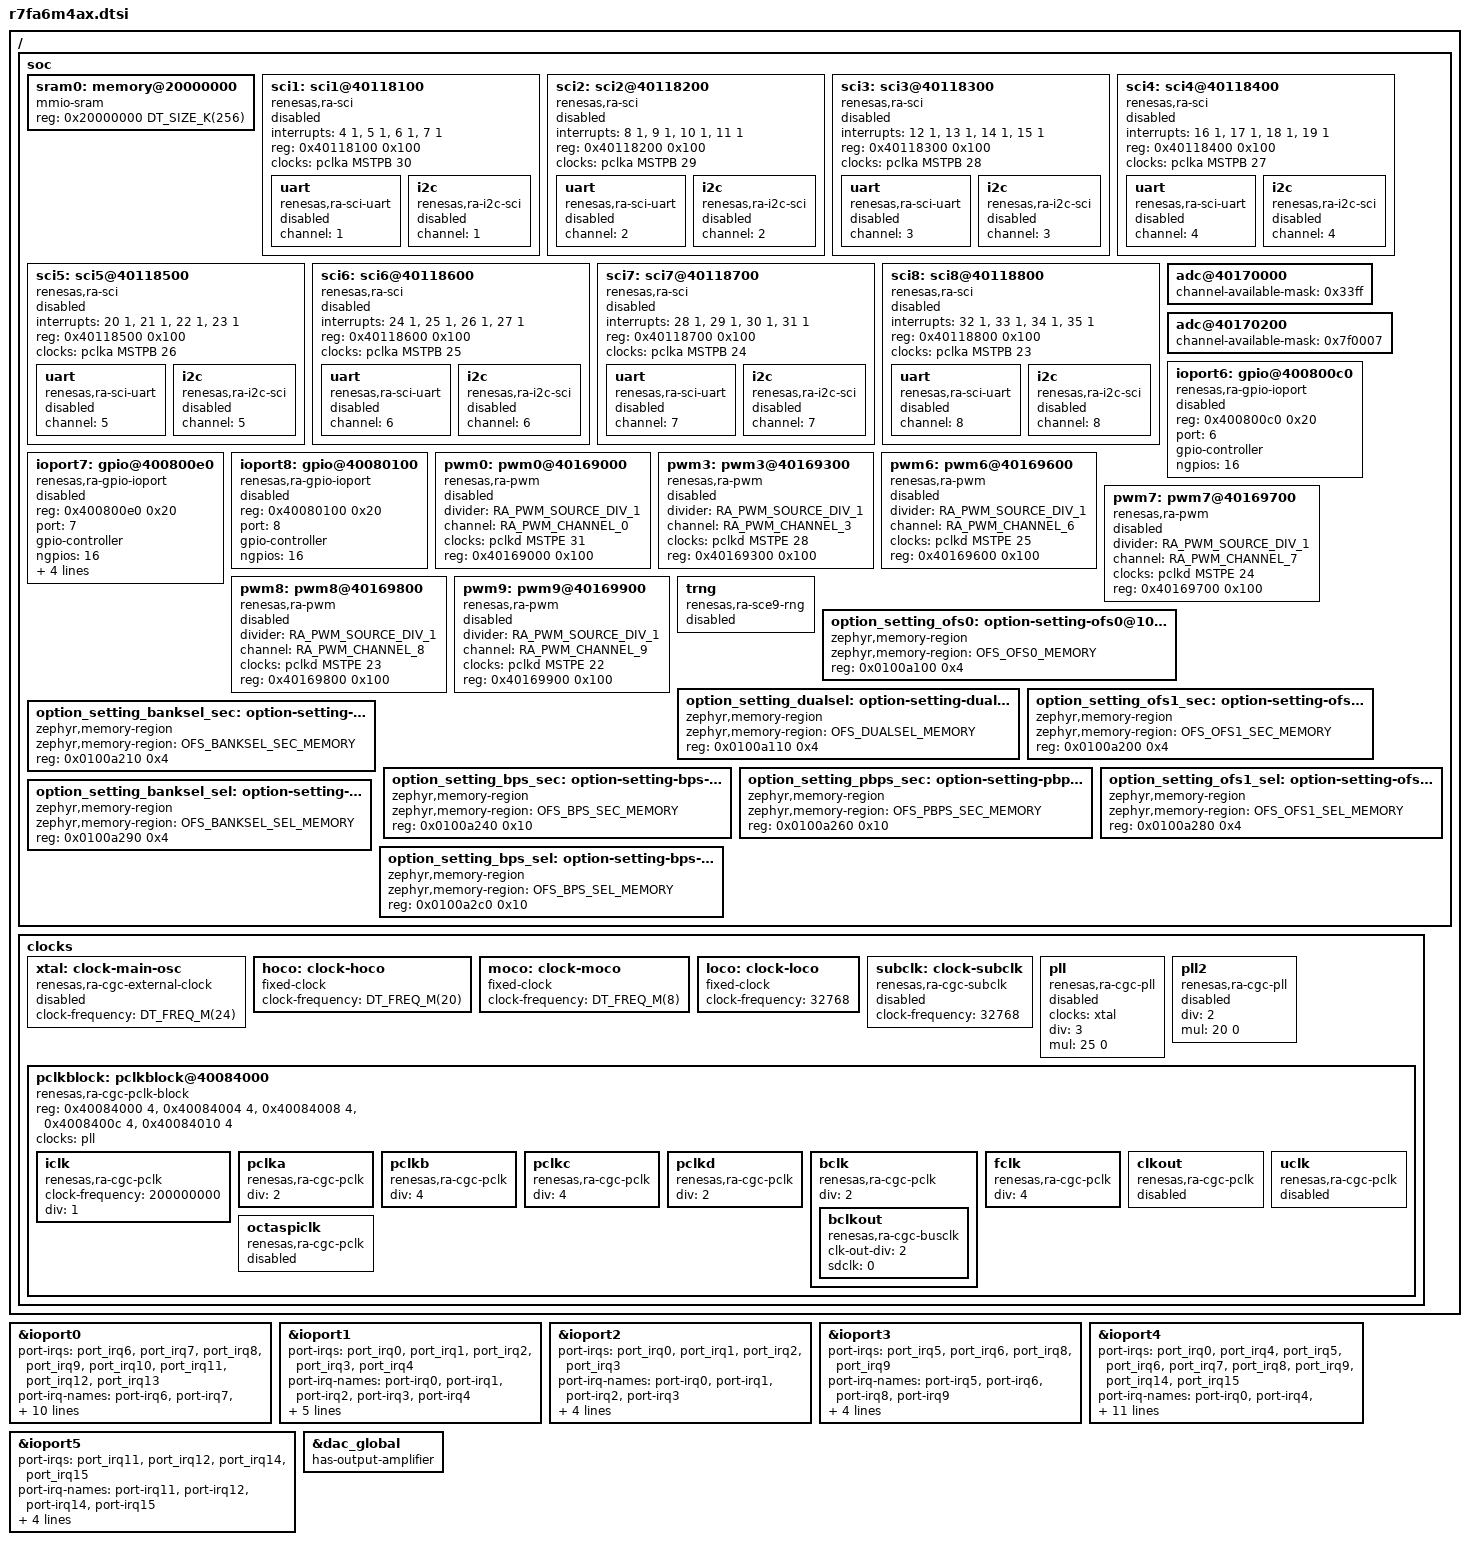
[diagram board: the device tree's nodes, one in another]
/*
 * Copyright (c) 2024-2025 Renesas Electronics Corporation
 *
 * SPDX-License-Identifier: Apache-2.0
 */

#include <arm/renesas/ra/ra6/ra6-cm33-common.dtsi>
#include <zephyr/dt-bindings/clock/ra_clock.h>
#include <zephyr/dt-bindings/pwm/ra_pwm.h>
#include <zephyr/dt-bindings/misc/renesas/ra-elc/ra6m4-elc.h>

/ {
	soc {
		sram0: memory@20000000 {
			compatible = "mmio-sram";
			reg = <0x20000000 DT_SIZE_K(256)>;
		};

		sci1: sci1@40118100 {
			compatible = "renesas,ra-sci";
			interrupts = <4 1>, <5 1>, <6 1>, <7 1>;
			interrupt-names = "rxi", "txi", "tei", "eri";
			reg = <0x40118100 0x100>;
			clocks = <&pclka MSTPB 30>;
			status = "disabled";

			uart {
				compatible = "renesas,ra-sci-uart";
				channel = <1>;
				status = "disabled";
			};

			i2c {
				compatible = "renesas,ra-i2c-sci";
				#address-cells = <1>;
				#size-cells = <0>;
				channel = <1>;
				status = "disabled";
			};
		};

		sci2: sci2@40118200 {
			compatible = "renesas,ra-sci";
			interrupts = <8 1>, <9 1>, <10 1>, <11 1>;
			interrupt-names = "rxi", "txi", "tei", "eri";
			reg = <0x40118200 0x100>;
			clocks = <&pclka MSTPB 29>;
			status = "disabled";

			uart {
				compatible = "renesas,ra-sci-uart";
				channel = <2>;
				status = "disabled";
			};

			i2c {
				compatible = "renesas,ra-i2c-sci";
				#address-cells = <1>;
				#size-cells = <0>;
				channel = <2>;
				status = "disabled";
			};
		};

		sci3: sci3@40118300 {
			compatible = "renesas,ra-sci";
			interrupts = <12 1>, <13 1>, <14 1>, <15 1>;
			interrupt-names = "rxi", "txi", "tei", "eri";
			reg = <0x40118300 0x100>;
			clocks = <&pclka MSTPB 28>;
			status = "disabled";

			uart {
				compatible = "renesas,ra-sci-uart";
				channel = <3>;
				status = "disabled";
			};

			i2c {
				compatible = "renesas,ra-i2c-sci";
				#address-cells = <1>;
				#size-cells = <0>;
				channel = <3>;
				status = "disabled";
			};
		};

		sci4: sci4@40118400 {
			compatible = "renesas,ra-sci";
			interrupts = <16 1>, <17 1>, <18 1>, <19 1>;
			interrupt-names = "rxi", "txi", "tei", "eri";
			reg = <0x40118400 0x100>;
			clocks = <&pclka MSTPB 27>;
			status = "disabled";

			uart {
				compatible = "renesas,ra-sci-uart";
				channel = <4>;
				status = "disabled";
			};

			i2c {
				compatible = "renesas,ra-i2c-sci";
				#address-cells = <1>;
				#size-cells = <0>;
				channel = <4>;
				status = "disabled";
			};
		};

		sci5: sci5@40118500 {
			compatible = "renesas,ra-sci";
			interrupts = <20 1>, <21 1>, <22 1>, <23 1>;
			interrupt-names = "rxi", "txi", "tei", "eri";
			reg = <0x40118500 0x100>;
			clocks = <&pclka MSTPB 26>;
			status = "disabled";

			uart {
				compatible = "renesas,ra-sci-uart";
				channel = <5>;
				status = "disabled";
			};

			i2c {
				compatible = "renesas,ra-i2c-sci";
				#address-cells = <1>;
				#size-cells = <0>;
				channel = <5>;
				status = "disabled";
			};
		};

		sci6: sci6@40118600 {
			compatible = "renesas,ra-sci";
			interrupts = <24 1>, <25 1>, <26 1>, <27 1>;
			interrupt-names = "rxi", "txi", "tei", "eri";
			reg = <0x40118600 0x100>;
			clocks = <&pclka MSTPB 25>;
			status = "disabled";

			uart {
				compatible = "renesas,ra-sci-uart";
				channel = <6>;
				status = "disabled";
			};

			i2c {
				compatible = "renesas,ra-i2c-sci";
				#address-cells = <1>;
				#size-cells = <0>;
				channel = <6>;
				status = "disabled";
			};
		};

		sci7: sci7@40118700 {
			compatible = "renesas,ra-sci";
			interrupts = <28 1>, <29 1>, <30 1>, <31 1>;
			interrupt-names = "rxi", "txi", "tei", "eri";
			reg = <0x40118700 0x100>;
			clocks = <&pclka MSTPB 24>;
			status = "disabled";

			uart {
				compatible = "renesas,ra-sci-uart";
				channel = <7>;
				status = "disabled";
			};

			i2c {
				compatible = "renesas,ra-i2c-sci";
				#address-cells = <1>;
				#size-cells = <0>;
				channel = <7>;
				status = "disabled";
			};
		};

		sci8: sci8@40118800 {
			compatible = "renesas,ra-sci";
			interrupts = <32 1>, <33 1>, <34 1>, <35 1>;
			interrupt-names = "rxi", "txi", "tei", "eri";
			reg = <0x40118800 0x100>;
			clocks = <&pclka MSTPB 23>;
			status = "disabled";

			uart {
				compatible = "renesas,ra-sci-uart";
				channel = <8>;
				status = "disabled";
			};

			i2c {
				compatible = "renesas,ra-i2c-sci";
				#address-cells = <1>;
				#size-cells = <0>;
				channel = <8>;
				status = "disabled";
			};
		};

		adc@40170000 {
			channel-available-mask = <0x33ff>;
		};

		adc@40170200 {
			channel-available-mask = <0x7f0007>;
		};

		ioport6: gpio@400800c0 {
			compatible = "renesas,ra-gpio-ioport";
			reg = <0x400800c0 0x20>;
			port = <6>;
			gpio-controller;
			#gpio-cells = <2>;
			ngpios = <16>;
			status = "disabled";
		};

		ioport7: gpio@400800e0 {
			compatible = "renesas,ra-gpio-ioport";
			reg = <0x400800e0 0x20>;
			port = <7>;
			gpio-controller;
			#gpio-cells = <2>;
			ngpios = <16>;
			status = "disabled";
		};

		ioport8: gpio@40080100 {
			compatible = "renesas,ra-gpio-ioport";
			reg = <0x40080100 0x20>;
			port = <8>;
			gpio-controller;
			#gpio-cells = <2>;
			ngpios = <16>;
			status = "disabled";
		};

		pwm0: pwm0@40169000 {
			compatible = "renesas,ra-pwm";
			divider = <RA_PWM_SOURCE_DIV_1>;
			channel = <RA_PWM_CHANNEL_0>;
			clocks = <&pclkd MSTPE 31>;
			reg = <0x40169000 0x100>;
			#pwm-cells = <3>;
			status = "disabled";
		};

		pwm3: pwm3@40169300 {
			compatible = "renesas,ra-pwm";
			divider = <RA_PWM_SOURCE_DIV_1>;
			channel = <RA_PWM_CHANNEL_3>;
			clocks = <&pclkd MSTPE 28>;
			reg = <0x40169300 0x100>;
			#pwm-cells = <3>;
			status = "disabled";
		};

		pwm6: pwm6@40169600 {
			compatible = "renesas,ra-pwm";
			divider = <RA_PWM_SOURCE_DIV_1>;
			channel = <RA_PWM_CHANNEL_6>;
			clocks = <&pclkd MSTPE 25>;
			reg = <0x40169600 0x100>;
			#pwm-cells = <3>;
			status = "disabled";
		};

		pwm7: pwm7@40169700 {
			compatible = "renesas,ra-pwm";
			divider = <RA_PWM_SOURCE_DIV_1>;
			channel = <RA_PWM_CHANNEL_7>;
			clocks = <&pclkd MSTPE 24>;
			reg = <0x40169700 0x100>;
			#pwm-cells = <3>;
			status = "disabled";
		};

		pwm8: pwm8@40169800 {
			compatible = "renesas,ra-pwm";
			divider = <RA_PWM_SOURCE_DIV_1>;
			channel = <RA_PWM_CHANNEL_8>;
			clocks = <&pclkd MSTPE 23>;
			reg = <0x40169800 0x100>;
			#pwm-cells = <3>;
			status = "disabled";
		};

		pwm9: pwm9@40169900 {
			compatible = "renesas,ra-pwm";
			divider = <RA_PWM_SOURCE_DIV_1>;
			channel = <RA_PWM_CHANNEL_9>;
			clocks = <&pclkd MSTPE 22>;
			reg = <0x40169900 0x100>;
			#pwm-cells = <3>;
			status = "disabled";
		};

		trng: trng {
			compatible = "renesas,ra-sce9-rng";
			status = "disabled";
		};

		option_setting_ofs0: option-setting-ofs0@100a100 {
			compatible = "zephyr,memory-region";
			zephyr,memory-region = "OFS_OFS0_MEMORY";
			reg = <0x0100a100 0x4>;
			status = "okay";
		};

		option_setting_dualsel: option-setting-dualsel@100a110 {
			compatible = "zephyr,memory-region";
			zephyr,memory-region = "OFS_DUALSEL_MEMORY";
			reg = <0x0100a110 0x4>;
			status = "okay";
		};

		option_setting_ofs1_sec: option-setting-ofs1-sec@100a200 {
			compatible = "zephyr,memory-region";
			zephyr,memory-region = "OFS_OFS1_SEC_MEMORY";
			reg = <0x0100a200 0x4>;
			status = "okay";
		};

		option_setting_banksel_sec: option-setting-banksel-sec@100a210 {
			compatible = "zephyr,memory-region";
			zephyr,memory-region = "OFS_BANKSEL_SEC_MEMORY";
			reg = <0x0100a210 0x4>;
			status = "okay";
		};

		option_setting_bps_sec: option-setting-bps-sec@100a240 {
			compatible = "zephyr,memory-region";
			zephyr,memory-region = "OFS_BPS_SEC_MEMORY";
			reg = <0x0100a240 0x10>;
			status = "okay";
		};

		option_setting_pbps_sec: option-setting-pbps-sec@100a260 {
			compatible = "zephyr,memory-region";
			zephyr,memory-region = "OFS_PBPS_SEC_MEMORY";
			reg = <0x0100a260 0x10>;
			status = "okay";
		};

		option_setting_ofs1_sel: option-setting-ofs1-sel@100a280 {
			compatible = "zephyr,memory-region";
			zephyr,memory-region = "OFS_OFS1_SEL_MEMORY";
			reg = <0x0100a280 0x4>;
			status = "okay";
		};

		option_setting_banksel_sel: option-setting-banksel-sel@100a290 {
			compatible = "zephyr,memory-region";
			zephyr,memory-region = "OFS_BANKSEL_SEL_MEMORY";
			reg = <0x0100a290 0x4>;
			status = "okay";
		};

		option_setting_bps_sel: option-setting-bps-sel@100a2c0 {
			compatible = "zephyr,memory-region";
			zephyr,memory-region = "OFS_BPS_SEL_MEMORY";
			reg = <0x0100a2c0 0x10>;
			status = "okay";
		};
	};

	clocks: clocks {
		#address-cells = <1>;
		#size-cells = <1>;

		xtal: clock-main-osc {
			compatible = "renesas,ra-cgc-external-clock";
			clock-frequency = <DT_FREQ_M(24)>;
			#clock-cells = <0>;
			status = "disabled";
		};

		hoco: clock-hoco {
			compatible = "fixed-clock";
			clock-frequency = <DT_FREQ_M(20)>;
			#clock-cells = <0>;
		};

		moco: clock-moco {
			compatible = "fixed-clock";
			clock-frequency = <DT_FREQ_M(8)>;
			#clock-cells = <0>;
		};

		loco: clock-loco {
			compatible = "fixed-clock";
			clock-frequency = <32768>;
			#clock-cells = <0>;
		};

		subclk: clock-subclk {
			compatible = "renesas,ra-cgc-subclk";
			clock-frequency = <32768>;
			#clock-cells = <0>;
			status = "disabled";
		};

		pll: pll {
			compatible = "renesas,ra-cgc-pll";
			#clock-cells = <0>;

			/* PLL */
			clocks = <&xtal>;
			div = <3>;
			mul = <25 0>;
			status = "disabled";
		};

		pll2: pll2 {
			compatible = "renesas,ra-cgc-pll";
			#clock-cells = <0>;

			/* PLL2 */
			div = <2>;
			mul = <20 0>;
			status = "disabled";
		};

		pclkblock: pclkblock@40084000 {
			compatible = "renesas,ra-cgc-pclk-block";
			reg = <0x40084000 4>, <0x40084004 4>, <0x40084008 4>,
			      <0x4008400c 4>, <0x40084010 4>;
			reg-names = "MSTPA", "MSTPB", "MSTPC",
				    "MSTPD", "MSTPE";
			#clock-cells = <0>;
			clocks = <&pll>;
			status = "okay";

			iclk: iclk {
				compatible = "renesas,ra-cgc-pclk";
				clock-frequency = <200000000>;
				div = <1>;
				#clock-cells = <2>;
				status = "okay";
			};

			pclka: pclka {
				compatible = "renesas,ra-cgc-pclk";
				div = <2>;
				#clock-cells = <2>;
				status = "okay";
			};

			pclkb: pclkb {
				compatible = "renesas,ra-cgc-pclk";
				div = <4>;
				#clock-cells = <2>;
				status = "okay";
			};

			pclkc: pclkc {
				compatible = "renesas,ra-cgc-pclk";
				div = <4>;
				#clock-cells = <2>;
				status = "okay";
			};

			pclkd: pclkd {
				compatible = "renesas,ra-cgc-pclk";
				div = <2>;
				#clock-cells = <2>;
				status = "okay";
			};

			bclk: bclk {
				compatible = "renesas,ra-cgc-pclk";
				div = <2>;
				#clock-cells = <2>;
				status = "okay";

				bclkout: bclkout {
					compatible = "renesas,ra-cgc-busclk";
					clk-out-div = <2>;
					sdclk = <0>;
					#clock-cells = <0>;
				};
			};

			fclk: fclk {
				compatible = "renesas,ra-cgc-pclk";
				div = <4>;
				#clock-cells = <2>;
				status = "okay";
			};

			clkout: clkout {
				compatible = "renesas,ra-cgc-pclk";
				#clock-cells = <2>;
				status = "disabled";
			};

			uclk: uclk {
				compatible = "renesas,ra-cgc-pclk";
				#clock-cells = <2>;
				status = "disabled";
			};

			octaspiclk: octaspiclk {
				compatible = "renesas,ra-cgc-pclk";
				#clock-cells = <2>;
				status = "disabled";
			};
		};
	};
};

&ioport0 {
	port-irqs = <&port_irq6 &port_irq7 &port_irq8
		     &port_irq9 &port_irq10 &port_irq11
		     &port_irq12 &port_irq13>;
	port-irq-names = "port-irq6",
			 "port-irq7",
			 "port-irq8",
			 "port-irq9",
			 "port-irq10",
			 "port-irq11",
			 "port-irq12",
			 "port-irq13";
	port-irq6-pins = <0>;
	port-irq7-pins = <1>;
	port-irq8-pins = <2>;
	port-irq9-pins = <4>;
	port-irq10-pins = <5>;
	port-irq11-pins = <6>;
	port-irq12-pins = <8>;
	port-irq13-pins = <9 15>;
};

&ioport1 {
	port-irqs = <&port_irq0 &port_irq1 &port_irq2
		     &port_irq3 &port_irq4>;
	port-irq-names = "port-irq0",
			 "port-irq1",
			 "port-irq2",
			 "port-irq3",
			 "port-irq4";
	port-irq0-pins = <5>;
	port-irq1-pins = <1 4>;
	port-irq2-pins = <0>;
	port-irq3-pins = <10>;
	port-irq4-pins = <11>;
};

&ioport2 {
	port-irqs = <&port_irq0 &port_irq1 &port_irq2
		     &port_irq3>;
	port-irq-names = "port-irq0",
			 "port-irq1",
			 "port-irq2",
			 "port-irq3";
	port-irq0-pins = <6>;
	port-irq1-pins = <5>;
	port-irq2-pins = <3 13>;
	port-irq3-pins = <2 12>;
};

&ioport3 {
	port-irqs = <&port_irq5 &port_irq6
		     &port_irq8 &port_irq9>;
	port-irq-names = "port-irq5",
			 "port-irq6",
			 "port-irq8",
			 "port-irq9";
	port-irq5-pins = <2>;
	port-irq6-pins = <1>;
	port-irq8-pins = <5>;
	port-irq9-pins = <4>;
};

&ioport4 {
	port-irqs = <&port_irq0 &port_irq4 &port_irq5
		     &port_irq6 &port_irq7 &port_irq8
		     &port_irq9 &port_irq14 &port_irq15>;
	port-irq-names = "port-irq0",
			 "port-irq4",
			 "port-irq5",
			 "port-irq6",
			 "port-irq7",
			 "port-irq8",
			 "port-irq9",
			 "port-irq14",
			 "port-irq15";
	port-irq0-pins = <0>;
	port-irq4-pins = <2 11>;
	port-irq5-pins = <1 10>;
	port-irq6-pins = <9>;
	port-irq7-pins = <8>;
	port-irq8-pins = <15>;
	port-irq9-pins = <14>;
	port-irq14-pins = <3>;
	port-irq15-pins = <4>;
};

&ioport5 {
	port-irqs = <&port_irq11 &port_irq12 &port_irq14
		     &port_irq15>;
	port-irq-names = "port-irq11",
			 "port-irq12",
			 "port-irq14",
			 "port-irq15";
	port-irq11-pins = <1>;
	port-irq12-pins = <2>;
	port-irq14-pins = <5 12>;
	port-irq15-pins = <6 11>;
};

&ioport7 {
	port-irqs = <&port_irq10 &port_irq11>;
	port-irq-names = "port-irq10",
			 "port-irq11";
	port-irq10-pins = <9>;
	port-irq11-pins = <8>;
};

&dac_global {
	has-output-amplifier;
};
